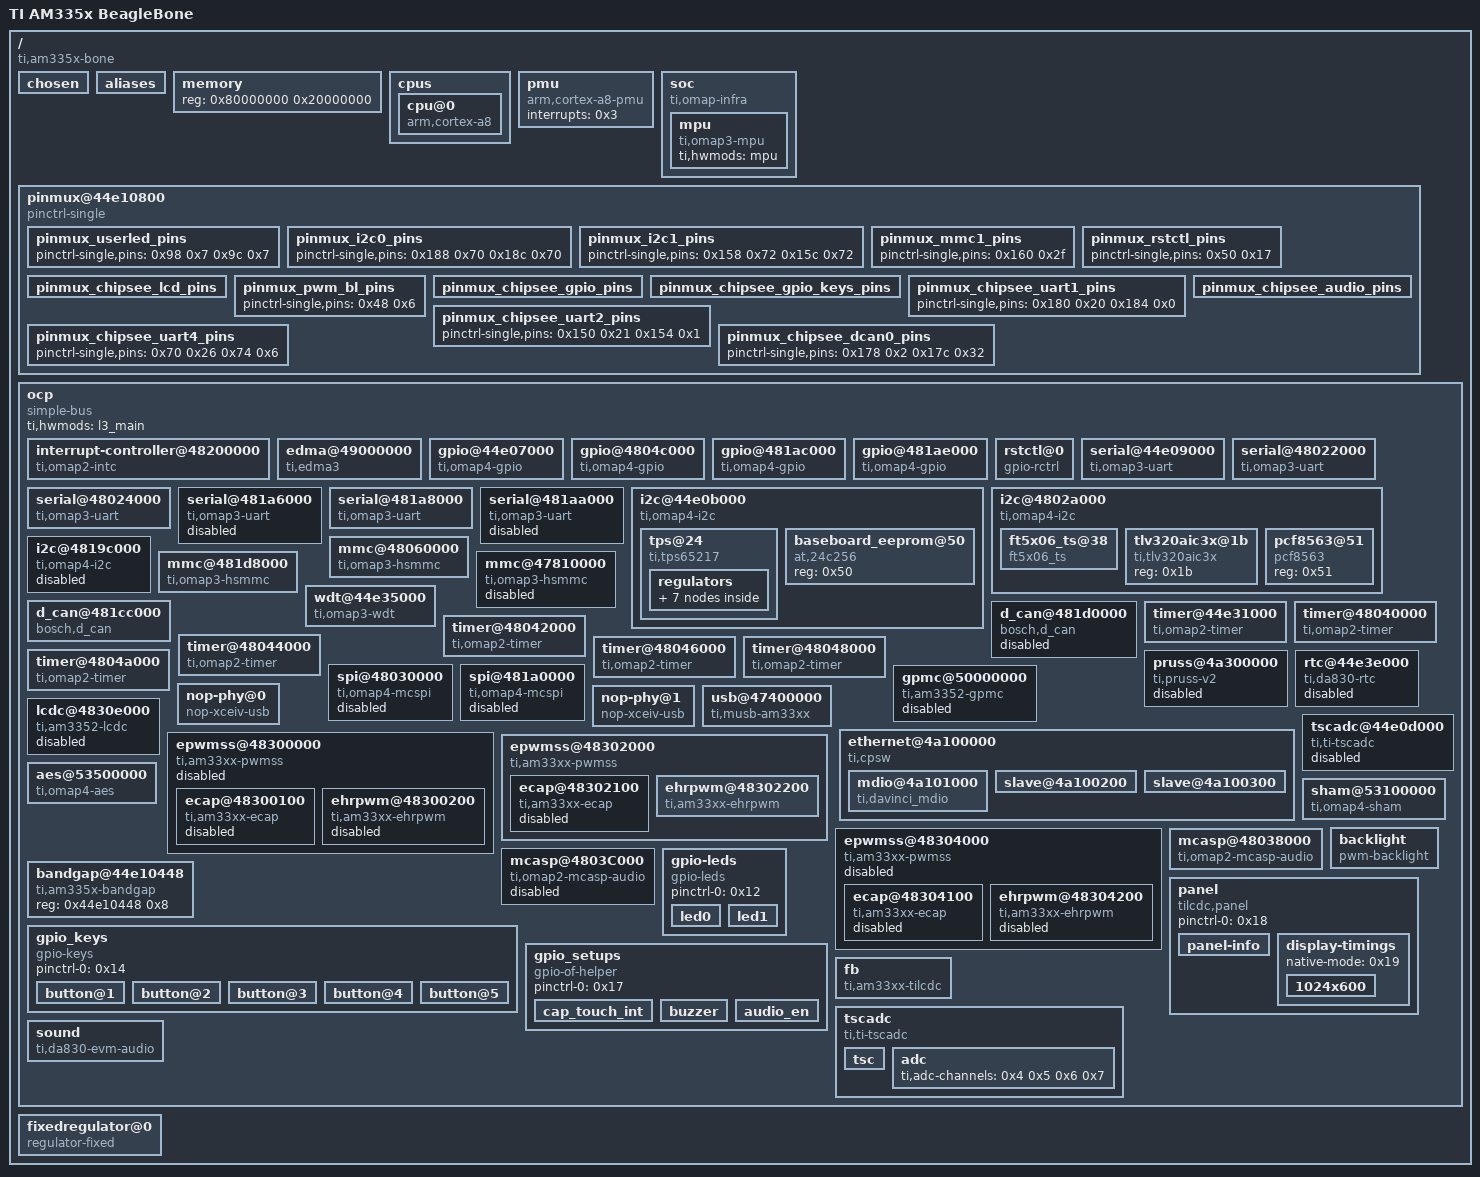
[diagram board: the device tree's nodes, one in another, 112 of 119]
/dts-v1/;

/ {
	#address-cells = <0x1>;
	#size-cells = <0x1>;
	compatible = "ti,am335x-bone", "ti,am33xx";
	interrupt-parent = <0x1>;
	model = "TI AM335x BeagleBone";

	chosen {
	};

	aliases {
		serial0 = "/ocp/serial@44e09000";
		serial1 = "/ocp/serial@48022000";
		serial2 = "/ocp/serial@48024000";
		serial3 = "/ocp/serial@481a6000";
		serial4 = "/ocp/serial@481a8000";
		serial5 = "/ocp/serial@481aa000";
	};

	memory {
		device_type = "memory";
		reg = <0x80000000 0x20000000>;
	};

	cpus {

		cpu@0 {
			compatible = "arm,cortex-a8";
			operating-points = <0xf4240 0x149970 0xc3500 0x13d620 0x927c0 0x10f7c0 0x493e0 0xec928>;
			voltage-tolerance = <0x2>;
			clock-latency = <0x493e0>;
			cpu0-supply = <0x2>;
			linux,phandle = <0x1c>;
			phandle = <0x1c>;
		};
	};

	pmu {
		compatible = "arm,cortex-a8-pmu";
		interrupts = <0x3>;
	};

	soc {
		compatible = "ti,omap-infra";

		mpu {
			compatible = "ti,omap3-mpu";
			ti,hwmods = "mpu";
		};
	};

	pinmux@44e10800 {
		compatible = "pinctrl-single";
		reg = <0x44e10800 0x238>;
		#address-cells = <0x1>;
		#size-cells = <0x0>;
		pinctrl-single,register-width = <0x20>;
		pinctrl-single,function-mask = <0x7f>;
		pinctrl-names = "default";
		linux,phandle = <0x1d>;
		phandle = <0x1d>;

		pinmux_userled_pins {
			pinctrl-single,pins = <0x98 0x7 0x9c 0x7>;
			linux,phandle = <0x12>;
			phandle = <0x12>;
		};

		pinmux_i2c0_pins {
			pinctrl-single,pins = <0x188 0x70 0x18c 0x70>;
			linux,phandle = <0x8>;
			phandle = <0x8>;
		};

		pinmux_i2c1_pins {
			pinctrl-single,pins = <0x158 0x72 0x15c 0x72>;
			linux,phandle = <0x9>;
			phandle = <0x9>;
		};

		pinmux_mmc1_pins {
			pinctrl-single,pins = <0x160 0x2f>;
			linux,phandle = <0xb>;
			phandle = <0xb>;
		};

		pinmux_rstctl_pins {
			pinctrl-single,pins = <0x50 0x17>;
			linux,phandle = <0x3>;
			phandle = <0x3>;
		};

		pinmux_chipsee_lcd_pins {
			pinctrl-single,pins = <0xa0 0x0 0xa4 0x0 0xa8 0x0 0xac 0x0 0xb0 0x0 0xb4 0x0 0xb8 0x0 0xbc 0x0 0xc0 0x0 0xc4 0x0 0xc8 0x0 0xcc 0x0 0xd0 0x0 0xd4 0x0 0xd8 0x0 0xdc 0x0 0x3c 0x11 0x38 0x11 0x34 0x11 0x30 0x11 0x2c 0x11 0x28 0x11 0x24 0x11 0x20 0x11 0xe0 0x0 0xe4 0x0 0xe8 0x0 0xec 0x0>;
			linux,phandle = <0x18>;
			phandle = <0x18>;
		};

		pinmux_pwm_bl_pins {
			pinctrl-single,pins = <0x48 0x6>;
			linux,phandle = <0xf>;
			phandle = <0xf>;
		};

		pinmux_chipsee_gpio_pins {
			pinctrl-single,pins = <0x44 0x27 0x94 0x7 0x90 0x7>;
			linux,phandle = <0x17>;
			phandle = <0x17>;
		};

		pinmux_chipsee_gpio_keys_pins {
			pinctrl-single,pins = <0x164 0x2f 0x78 0x2f 0x40 0x2f 0x4c 0x2f 0x1a4 0x2f>;
			linux,phandle = <0x14>;
			phandle = <0x14>;
		};

		pinmux_chipsee_uart1_pins {
			pinctrl-single,pins = <0x180 0x20 0x184 0x0>;
			linux,phandle = <0x5>;
			phandle = <0x5>;
		};

		pinmux_chipsee_uart2_pins {
			pinctrl-single,pins = <0x150 0x21 0x154 0x1>;
			linux,phandle = <0x6>;
			phandle = <0x6>;
		};

		pinmux_chipsee_uart4_pins {
			pinctrl-single,pins = <0x70 0x26 0x74 0x6>;
			linux,phandle = <0x7>;
			phandle = <0x7>;
		};

		pinmux_chipsee_dcan0_pins {
			pinctrl-single,pins = <0x178 0x2 0x17c 0x32>;
			linux,phandle = <0xd>;
			phandle = <0xd>;
		};

		pinmux_chipsee_audio_pins {
			pinctrl-single,pins = <0x190 0x20 0x194 0x20 0x198 0x20 0x19c 0x22>;
			linux,phandle = <0x10>;
			phandle = <0x10>;
		};
	};
	
	
	
	
	
	
	
	
	
	
	
	
	
	
	
	
	
	
	
	
	ocp {
		compatible = "simple-bus";
		#address-cells = <0x1>;
		#size-cells = <0x1>;
		ranges;
		ti,hwmods = "l3_main";
		linux,phandle = <0x1e>;
		phandle = <0x1e>;

		interrupt-controller@48200000 {
			compatible = "ti,omap2-intc";
			interrupt-controller;
			#interrupt-cells = <0x1>;
			ti,intc-size = <0x80>;
			reg = <0x48200000 0x1000>;
			linux,phandle = <0x1>;
			phandle = <0x1>;
		};

		edma@49000000 {
			compatible = "ti,edma3";
			ti,hwmods = "tpcc", "tptc0", "tptc1", "tptc2";
			reg = <0x49000000 0x10000 0x44e10f90 0x40>;
			interrupt-parent = <0x1>;
			interrupts = <0xc 0xd 0xe>;
			#dma-cells = <0x1>;
			dma-channels = <0x40>;
			ti,edma-regions = <0x4>;
			ti,edma-slots = <0x100>;
			ti,edma-queue-tc-map = <0x0 0x0 0x1 0x1 0x2 0x2>;
			ti,edma-queue-priority-map = <0x0 0x0 0x1 0x1 0x2 0x2>;
			ti,edma-default-queue = <0x1>;
			ti,edma-xbar-event-map = <0x20 0xc 0x1e 0x14>;
			linux,phandle = <0xa>;
			phandle = <0xa>;
		};

		gpio@44e07000 {
			compatible = "ti,omap4-gpio";
			ti,hwmods = "gpio1";
			gpio-controller;
			#gpio-cells = <0x2>;
			interrupt-controller;
			#interrupt-cells = <0x1>;
			reg = <0x44e07000 0x1000>;
			interrupts = <0x60>;
			linux,phandle = <0x15>;
			phandle = <0x15>;
		};

		gpio@4804c000 {
			compatible = "ti,omap4-gpio";
			ti,hwmods = "gpio2";
			gpio-controller;
			#gpio-cells = <0x2>;
			interrupt-controller;
			#interrupt-cells = <0x1>;
			reg = <0x4804c000 0x1000>;
			interrupts = <0x62>;
			linux,phandle = <0x4>;
			phandle = <0x4>;
		};

		gpio@481ac000 {
			compatible = "ti,omap4-gpio";
			ti,hwmods = "gpio3";
			gpio-controller;
			#gpio-cells = <0x2>;
			interrupt-controller;
			#interrupt-cells = <0x1>;
			reg = <0x481ac000 0x1000>;
			interrupts = <0x20>;
			linux,phandle = <0x13>;
			phandle = <0x13>;
		};

		gpio@481ae000 {
			compatible = "ti,omap4-gpio";
			ti,hwmods = "gpio4";
			gpio-controller;
			#gpio-cells = <0x2>;
			interrupt-controller;
			#interrupt-cells = <0x1>;
			reg = <0x481ae000 0x1000>;
			interrupts = <0x3e>;
			linux,phandle = <0x16>;
			phandle = <0x16>;
		};

		rstctl@0 {
			status = "okay";
			compatible = "gpio-rctrl";
			pinctrl-names = "default";
			pinctrl-0 = <0x3>;
			#reset-cells = <0x2>;
			gpios = <0x4 0x14 0x0>;
			gpio-names = "eMMC_RSTn";
			linux,phandle = <0x1f>;
			phandle = <0x1f>;
		};

		serial@44e09000 {
			compatible = "ti,omap3-uart";
			ti,hwmods = "uart1";
			clock-frequency = <0x2dc6c00>;
			reg = <0x44e09000 0x2000>;
			interrupts = <0x48>;
			status = "okay";
			linux,phandle = <0x20>;
			phandle = <0x20>;
		};

		serial@48022000 {
			compatible = "ti,omap3-uart";
			ti,hwmods = "uart2";
			clock-frequency = <0x2dc6c00>;
			reg = <0x48022000 0x2000>;
			interrupts = <0x49>;
			status = "okay";
			pinctrl-names = "default";
			pinctrl-0 = <0x5>;
			linux,phandle = <0x21>;
			phandle = <0x21>;
		};

		serial@48024000 {
			compatible = "ti,omap3-uart";
			ti,hwmods = "uart3";
			clock-frequency = <0x2dc6c00>;
			reg = <0x48024000 0x2000>;
			interrupts = <0x4a>;
			status = "okay";
			pinctrl-names = "default";
			pinctrl-0 = <0x6>;
			linux,phandle = <0x22>;
			phandle = <0x22>;
		};

		serial@481a6000 {
			compatible = "ti,omap3-uart";
			ti,hwmods = "uart4";
			clock-frequency = <0x2dc6c00>;
			reg = <0x481a6000 0x2000>;
			interrupts = <0x2c>;
			status = "disabled";
			linux,phandle = <0x23>;
			phandle = <0x23>;
		};

		serial@481a8000 {
			compatible = "ti,omap3-uart";
			ti,hwmods = "uart5";
			clock-frequency = <0x2dc6c00>;
			reg = <0x481a8000 0x2000>;
			interrupts = <0x2d>;
			status = "okay";
			pinctrl-names = "default";
			pinctrl-0 = <0x7>;
			linux,phandle = <0x24>;
			phandle = <0x24>;
		};

		serial@481aa000 {
			compatible = "ti,omap3-uart";
			ti,hwmods = "uart6";
			clock-frequency = <0x2dc6c00>;
			reg = <0x481aa000 0x2000>;
			interrupts = <0x2e>;
			status = "disabled";
			linux,phandle = <0x25>;
			phandle = <0x25>;
		};

		i2c@44e0b000 {
			compatible = "ti,omap4-i2c";
			#address-cells = <0x1>;
			#size-cells = <0x0>;
			ti,hwmods = "i2c1";
			reg = <0x44e0b000 0x1000>;
			interrupts = <0x46>;
			status = "okay";
			clock-frequency = <0x61a80>;
			pinctrl-names = "default";
			pinctrl-0 = <0x8>;
			linux,phandle = <0x26>;
			phandle = <0x26>;

			tps@24 {
				reg = <0x24>;
				compatible = "ti,tps65217";
				ti,pmic-shutdown-controller;
				interrupt-parent = <0x1>;
				interrupts = <0x7>;
				linux,phandle = <0x27>;
				phandle = <0x27>;

				regulators {
					#address-cells = <0x1>;
					#size-cells = <0x0>;

					regulator@0 {
						reg = <0x0>;
						regulator-compatible = "dcdc1";
						regulator-always-on;
						linux,phandle = <0x28>;
						phandle = <0x28>;
					};

					regulator@1 {
						reg = <0x1>;
						regulator-compatible = "dcdc2";
						regulator-name = "vdd_mpu";
						regulator-min-microvolt = <0xe1d48>;
						regulator-max-microvolt = <0x1437c8>;
						regulator-boot-on;
						regulator-always-on;
						linux,phandle = <0x2>;
						phandle = <0x2>;
					};

					regulator@2 {
						reg = <0x2>;
						regulator-compatible = "dcdc3";
						regulator-name = "vdd_core";
						regulator-min-microvolt = <0xe1d48>;
						regulator-max-microvolt = <0x118c30>;
						regulator-boot-on;
						regulator-always-on;
						linux,phandle = <0x29>;
						phandle = <0x29>;
					};

					regulator@3 {
						reg = <0x3>;
						regulator-compatible = "ldo1";
						regulator-always-on;
						linux,phandle = <0x2a>;
						phandle = <0x2a>;
					};

					regulator@4 {
						reg = <0x4>;
						regulator-compatible = "ldo2";
						regulator-always-on;
						linux,phandle = <0x2b>;
						phandle = <0x2b>;
					};

					regulator@5 {
						reg = <0x5>;
						regulator-compatible = "ldo3";
						regulator-min-microvolt = <0x1b7740>;
						regulator-max-microvolt = <0x1b7740>;
						regulator-always-on;
						linux,phandle = <0x2c>;
						phandle = <0x2c>;
					};

					regulator@6 {
						reg = <0x6>;
						regulator-compatible = "ldo4";
						regulator-always-on;
						linux,phandle = <0x2d>;
						phandle = <0x2d>;
					};
				};
			};

			baseboard_eeprom@50 {
				compatible = "at,24c256";
				reg = <0x50>;
				linux,phandle = <0x2e>;
				phandle = <0x2e>;
			};
		};

		i2c@4802a000 {
			compatible = "ti,omap4-i2c";
			#address-cells = <0x1>;
			#size-cells = <0x0>;
			ti,hwmods = "i2c2";
			reg = <0x4802a000 0x1000>;
			interrupts = <0x47>;
			status = "okay";
			clock-frequency = <0x61a80>;
			pinctrl-names = "default";
			pinctrl-0 = <0x9>;
			linux,phandle = <0x2f>;
			phandle = <0x2f>;

			ft5x06_ts@38 {
				compatible = "ft5x06_ts";
				reg = <0x38>;
				interrupt-parent = <0x4>;
				interrupts = <0x11>;
				linux,phandle = <0x30>;
				phandle = <0x30>;
			};

			tlv320aic3x@1b {
				compatible = "ti,tlv320aic3x";
				reg = <0x1b>;
				status = "okay";
				linux,phandle = <0x1a>;
				phandle = <0x1a>;
			};

			pcf8563@51 {
				compatible = "pcf8563";
				reg = <0x51>;
				status = "okay";
				linux,phandle = <0x31>;
				phandle = <0x31>;
			};
		};

		i2c@4819c000 {
			compatible = "ti,omap4-i2c";
			#address-cells = <0x1>;
			#size-cells = <0x0>;
			ti,hwmods = "i2c3";
			reg = <0x4819c000 0x1000>;
			interrupts = <0x1e>;
			status = "disabled";
			linux,phandle = <0x32>;
			phandle = <0x32>;
		};

		mmc@48060000 {
			compatible = "ti,omap3-hsmmc";
			ti,hwmods = "mmc1";
			ti,dual-volt;
			ti,needs-special-reset;
			ti,needs-special-hs-handling;
			dmas = <0xa 0x18 0xa 0x19>;
			dma-names = "tx", "rx";
			status = "okay";
			pinctrl-names = "default";
			pinctrl-0 = <0xb>;
			bus-width = <0x8>;
			non-removable;
			ti,vcc-aux-disable-is-sleep;
			linux,phandle = <0x33>;
			phandle = <0x33>;
		};

		mmc@481d8000 {
			compatible = "ti,omap3-hsmmc";
			ti,hwmods = "mmc2";
			ti,needs-special-reset;
			ti,needs-special-hs-handling;
			dmas = <0xa 0x2 0xa 0x3>;
			dma-names = "tx", "rx";
			status = "okay";
			vmmc-supply = <0xc>;
			pinctrl-names = "default";
			pinctrl-0 = <0xdeadbeef>;
			bus-width = <0x8>;
			non-removable;
			ti,vcc-aux-disable-is-sleep;
			linux,phandle = <0x34>;
			phandle = <0x34>;
		};

		mmc@47810000 {
			compatible = "ti,omap3-hsmmc";
			ti,hwmods = "mmc3";
			ti,needs-special-reset;
			ti,needs-special-hs-handling;
			status = "disabled";
			linux,phandle = <0x35>;
			phandle = <0x35>;
		};

		wdt@44e35000 {
			compatible = "ti,omap3-wdt";
			ti,hwmods = "wd_timer2";
			reg = <0x44e35000 0x1000>;
			interrupts = <0x5b>;
			linux,phandle = <0x36>;
			phandle = <0x36>;
		};

		d_can@481cc000 {
			compatible = "bosch,d_can";
			ti,hwmods = "d_can0";
			reg = <0x481cc000 0x2000>;
			interrupts = <0x34>;
			status = "okay";
			pinctrl-names = "default";
			pinctrl-0 = <0xd>;
			linux,phandle = <0x37>;
			phandle = <0x37>;
		};

		d_can@481d0000 {
			compatible = "bosch,d_can";
			ti,hwmods = "d_can1";
			reg = <0x481d0000 0x2000>;
			interrupts = <0x37>;
			status = "disabled";
			linux,phandle = <0x38>;
			phandle = <0x38>;
		};

		timer@44e31000 {
			compatible = "ti,omap2-timer";
			reg = <0x44e31000 0x400>;
			interrupts = <0x43>;
			ti,hwmods = "timer1";
			ti,timer-alwon;
			linux,phandle = <0x39>;
			phandle = <0x39>;
		};

		timer@48040000 {
			compatible = "ti,omap2-timer";
			reg = <0x48040000 0x400>;
			interrupts = <0x44>;
			ti,hwmods = "timer2";
			linux,phandle = <0x3a>;
			phandle = <0x3a>;
		};

		timer@48042000 {
			compatible = "ti,omap2-timer";
			reg = <0x48042000 0x400>;
			interrupts = <0x45>;
			ti,hwmods = "timer3";
			linux,phandle = <0x3b>;
			phandle = <0x3b>;
		};

		timer@48044000 {
			compatible = "ti,omap2-timer";
			reg = <0x48044000 0x400>;
			interrupts = <0x5c>;
			ti,hwmods = "timer4";
			ti,timer-pwm;
			linux,phandle = <0x3c>;
			phandle = <0x3c>;
		};

		timer@48046000 {
			compatible = "ti,omap2-timer";
			reg = <0x48046000 0x400>;
			interrupts = <0x5d>;
			ti,hwmods = "timer5";
			ti,timer-pwm;
			linux,phandle = <0x3d>;
			phandle = <0x3d>;
		};

		timer@48048000 {
			compatible = "ti,omap2-timer";
			reg = <0x48048000 0x400>;
			interrupts = <0x5e>;
			ti,hwmods = "timer6";
			ti,timer-pwm;
			linux,phandle = <0x3e>;
			phandle = <0x3e>;
		};

		timer@4804a000 {
			compatible = "ti,omap2-timer";
			reg = <0x4804a000 0x400>;
			interrupts = <0x5f>;
			ti,hwmods = "timer7";
			ti,timer-pwm;
			linux,phandle = <0x3f>;
			phandle = <0x3f>;
		};

		pruss@4a300000 {
			compatible = "ti,pruss-v2";
			ti,hwmods = "pruss";
			ti,deassert-hard-reset = "pruss", "pruss";
			reg = <0x4a300000 0x80000>;
			ti,pintc-offset = <0x20000>;
			interrupt-parent = <0x1>;
			status = "disabled";
			interrupts = <0x14 0x15 0x16 0x17 0x18 0x19 0x1a 0x1b>;
			linux,phandle = <0x40>;
			phandle = <0x40>;
		};

		rtc@44e3e000 {
			compatible = "ti,da830-rtc";
			reg = <0x44e3e000 0x1000>;
			interrupts = <0x4b 0x4c>;
			ti,hwmods = "rtc";
			status = "disabled";
		};

		spi@48030000 {
			compatible = "ti,omap4-mcspi";
			#address-cells = <0x1>;
			#size-cells = <0x0>;
			reg = <0x48030000 0x400>;
			interrupt = <0x41>;
			ti,spi-num-cs = <0x2>;
			ti,hwmods = "spi0";
			dmas = <0xa 0x10 0xa 0x11 0xa 0x12 0xa 0x13>;
			dma-names = "tx0", "rx0", "tx1", "rx1";
			status = "disabled";
			linux,phandle = <0x41>;
			phandle = <0x41>;
		};

		spi@481a0000 {
			compatible = "ti,omap4-mcspi";
			#address-cells = <0x1>;
			#size-cells = <0x0>;
			reg = <0x481a0000 0x400>;
			interrupt = <0x7d>;
			ti,spi-num-cs = <0x2>;
			ti,hwmods = "spi1";
			dmas = <0xa 0x2a 0xa 0x2b 0xa 0x2c 0xa 0x2d>;
			dma-names = "tx0", "rx0", "tx1", "rx1";
			status = "disabled";
			linux,phandle = <0x42>;
			phandle = <0x42>;
		};

		gpmc@50000000 {
			compatible = "ti,am3352-gpmc";
			ti,hwmods = "gpmc";
			reg = <0x50000000 0x1000000>;
			interrupts = <0x64>;
			gpmc,num-cs = <0x7>;
			gpmc,num-waitpins = <0x2>;
			#address-cells = <0x2>;
			#size-cells = <0x1>;
			status = "disabled";
			linux,phandle = <0x43>;
			phandle = <0x43>;
		};

		nop-phy@0 {
			compatible = "nop-xceiv-usb";
		};

		nop-phy@1 {
			compatible = "nop-xceiv-usb";
		};

		usb@47400000 {
			compatible = "ti,musb-am33xx";
			reg = <0x47400000 0x1000 0x47401000 0x800 0x47401800 0x800>;
			interrupts = <0x11 0x12 0x13>;
			multipoint = <0x1>;
			num-eps = <0x10>;
			ram-bits = <0xc>;
			port0-mode = <0x1>;
			port1-mode = <0x1>;
			power = <0xfa>;
			ti,hwmods = "usb_otg_hs";
			status = "okay";
			interface_type = <0x1>;
			linux,phandle = <0x44>;
			phandle = <0x44>;
		};

		ethernet@4a100000 {
			compatible = "ti,cpsw";
			ti,hwmods = "cpgmac0";
			cpdma_channels = <0x8>;
			ale_entries = <0x400>;
			bd_ram_size = <0x2000>;
			no_bd_ram = <0x0>;
			rx_descs = <0x40>;
			mac_control = <0x20>;
			slaves = <0x2>;
			cpts_active_slave = <0x0>;
			cpts_clock_mult = <0x80000000>;
			cpts_clock_shift = <0x1d>;
			reg = <0x4a100000 0x800 0x4a101200 0x100>;
			#address-cells = <0x1>;
			#size-cells = <0x1>;
			interrupt-parent = <0x1>;
			interrupts = <0x28 0x29 0x2a 0x2b>;
			ranges;
			disable-napi;
			linux,phandle = <0x45>;
			phandle = <0x45>;

			mdio@4a101000 {
				compatible = "ti,davinci_mdio";
				#address-cells = <0x1>;
				#size-cells = <0x0>;
				ti,hwmods = "davinci_mdio";
				bus_freq = <0xf4240>;
				reg = <0x4a101000 0x100>;
				linux,phandle = <0xe>;
				phandle = <0xe>;
			};

			slave@4a100200 {
				mac-address = [00 00 00 00 00 00];
				phy_id = <0xe 0x0>;
				linux,phandle = <0x46>;
				phandle = <0x46>;
			};

			slave@4a100300 {
				mac-address = [00 00 00 00 00 00];
				phy_id = <0xe 0x1>;
				linux,phandle = <0x47>;
				phandle = <0x47>;
			};
		};

		tscadc@44e0d000 {
			compatible = "ti,ti-tscadc";
			reg = <0x44e0d000 0x1000>;
			interrupt-parent = <0x1>;
			interrupts = <0x10>;
			ti,hwmods = "adc_tsc";
			status = "disabled";
			linux,phandle = <0x48>;
			phandle = <0x48>;
		};

		lcdc@4830e000 {
			compatible = "ti,am3352-lcdc", "ti,da830-lcdc";
			reg = <0x4830e000 0x1000>;
			interrupts = <0x24>;
			status = "disabled";
			ti,hwmods = "lcdc";
			linux,phandle = <0x49>;
			phandle = <0x49>;
		};

		epwmss@48300000 {
			compatible = "ti,am33xx-pwmss";
			reg = <0x48300000 0x10>;
			ti,hwmods = "epwmss0";
			#address-cells = <0x1>;
			#size-cells = <0x1>;
			status = "disabled";
			ranges = <0x48300100 0x48300100 0x80 0x48300180 0x48300180 0x80 0x48300200 0x48300200 0x80>;
			linux,phandle = <0x4a>;
			phandle = <0x4a>;

			ecap@48300100 {
				compatible = "ti,am33xx-ecap";
				#pwm-cells = <0x3>;
				reg = <0x48300100 0x80>;
				ti,hwmods = "ecap0";
				status = "disabled";
				linux,phandle = <0x4b>;
				phandle = <0x4b>;
			};

			ehrpwm@48300200 {
				compatible = "ti,am33xx-ehrpwm";
				#pwm-cells = <0x3>;
				reg = <0x48300200 0x80>;
				ti,hwmods = "ehrpwm0";
				status = "disabled";
				linux,phandle = <0x4c>;
				phandle = <0x4c>;
			};
		};

		epwmss@48302000 {
			compatible = "ti,am33xx-pwmss";
			reg = <0x48302000 0x10>;
			ti,hwmods = "epwmss1";
			#address-cells = <0x1>;
			#size-cells = <0x1>;
			status = "okay";
			ranges = <0x48302100 0x48302100 0x80 0x48302180 0x48302180 0x80 0x48302200 0x48302200 0x80>;
			linux,phandle = <0x4d>;
			phandle = <0x4d>;

			ecap@48302100 {
				compatible = "ti,am33xx-ecap";
				#pwm-cells = <0x3>;
				reg = <0x48302100 0x80>;
				ti,hwmods = "ecap1";
				status = "disabled";
				linux,phandle = <0x4e>;
				phandle = <0x4e>;
			};

			ehrpwm@48302200 {
				compatible = "ti,am33xx-ehrpwm";
				#pwm-cells = <0x3>;
				reg = <0x48302200 0x80>;
				ti,hwmods = "ehrpwm1";
				status = "okay";
				pinctrl-names = "default";
				pinctrl-0 = <0xf>;
				linux,phandle = <0x11>;
				phandle = <0x11>;
			};
		};

		epwmss@48304000 {
			compatible = "ti,am33xx-pwmss";
			reg = <0x48304000 0x10>;
			ti,hwmods = "epwmss2";
			#address-cells = <0x1>;
			#size-cells = <0x1>;
			status = "disabled";
			ranges = <0x48304100 0x48304100 0x80 0x48304180 0x48304180 0x80 0x48304200 0x48304200 0x80>;
			linux,phandle = <0x4f>;
			phandle = <0x4f>;

			ecap@48304100 {
				compatible = "ti,am33xx-ecap";
				#pwm-cells = <0x3>;
				reg = <0x48304100 0x80>;
				ti,hwmods = "ecap2";
				status = "disabled";
				linux,phandle = <0x50>;
				phandle = <0x50>;
			};

			ehrpwm@48304200 {
				compatible = "ti,am33xx-ehrpwm";
				#pwm-cells = <0x3>;
				reg = <0x48304200 0x80>;
				ti,hwmods = "ehrpwm2";
				status = "disabled";
				linux,phandle = <0x51>;
				phandle = <0x51>;
			};
		};

		sham@53100000 {
			compatible = "ti,omap4-sham";
			ti,hwmods = "sham";
			#address-cells = <0x1>;
			#size-cells = <0x0>;
			reg = <0x53100000 0x200>;
			interrupt-parent = <0x1>;
			interrupts = <0x6d>;
			dmas = <0xa 0x24>;
			dma-names = "rx";
			status = "okay";
			linux,phandle = <0x52>;
			phandle = <0x52>;
		};

		aes@53500000 {
			compatible = "ti,omap4-aes";
			ti,hwmods = "aes";
			#address-cells = <0x1>;
			#size-cells = <0x0>;
			reg = <0x53500000 0xa0>;
			interrupt-parent = <0x1>;
			interrupts = <0x66>;
			dmas = <0xa 0x6 0xa 0x5>;
			dma-names = "tx", "rx";
			status = "okay";
			linux,phandle = <0x53>;
			phandle = <0x53>;
		};

		mcasp@48038000 {
			compatible = "ti,omap2-mcasp-audio";
			#address-cells = <0x1>;
			#size-cells = <0x0>;
			ti,hwmods = "mcasp0";
			reg = <0x48038000 0x2000>;
			interrupts = <0x50 0x51>;
			status = "okay";
			asp-chan-q = <0x2>;
			tx-dma-offset = <0x46000000>;
			rx-dma-offset = <0x46000000>;
			dmas = <0xa 0x8 0xa 0x9>;
			dma-names = "tx", "rx";
			pinctrl-names = "default";
			pinctrl-0 = <0x10>;
			op-mode = <0x0>;
			tdm-slots = <0x2>;
			num-serializer = <0x10>;
			serial-dir = <0x1 0x0 0x2 0x0 0x0 0x0 0x0 0x0 0x0 0x0 0x0 0x0 0x0 0x0 0x0 0x0>;
			tx-num-evt = <0x1>;
			rx-num-evt = <0x1>;
			linux,phandle = <0x1b>;
			phandle = <0x1b>;
		};

		mcasp@4803C000 {
			compatible = "ti,omap2-mcasp-audio";
			#address-cells = <0x1>;
			#size-cells = <0x0>;
			ti,hwmods = "mcasp1";
			reg = <0x4803c000 0x2000>;
			interrupts = <0x52 0x53>;
			status = "disabled";
			asp-chan-q = <0x2>;
			tx-dma-offset = <0x46400000>;
			rx-dma-offset = <0x46400000>;
			dmas = <0xa 0xa 0xa 0xb>;
			dma-names = "tx", "rx";
			linux,phandle = <0x54>;
			phandle = <0x54>;
		};

		bandgap@44e10448 {
			compatible = "ti,am335x-bandgap";
			reg = <0x44e10448 0x8>;
		};

		backlight {
			compatible = "pwm-backlight";
			pwms = <0x11 0x0 0x7a120 0x0>;
			brightness-levels = <0x0 0x1 0x2 0x3 0x4 0x5 0x6 0x7 0x8 0x9 0xa 0xb 0xc 0xd 0xe 0xf 0x10 0x11 0x12 0x13 0x14 0x15 0x16 0x17 0x18 0x19 0x1a 0x1b 0x1c 0x1d 0x1e 0x1f 0x20 0x21 0x22 0x23 0x24 0x25 0x26 0x27 0x28 0x29 0x2a 0x2b 0x2c 0x2d 0x2e 0x2f 0x30 0x31 0x32 0x33 0x34 0x35 0x36 0x37 0x38 0x39 0x3a 0x3b 0x3c 0x3d 0x3e 0x3f 0x40 0x41 0x42 0x43 0x44 0x45 0x46 0x47 0x48 0x49 0x4a 0x4b 0x4c 0x4d 0x4e 0x4f 0x50 0x51 0x52 0x53 0x54 0x55 0x56 0x57 0x58 0x59 0x5a 0x5b 0x5c 0x5d 0x5e 0x5f 0x60 0x61 0x62 0x63 0x64>;
			default-brightness-level = <0x65>;
		};

		gpio-leds {
			compatible = "gpio-leds";
			pinctrl-names = "default";
			pinctrl-0 = <0x12>;

			led0 {
				label = "beaglebone:green:usr0";
				gpios = <0x13 0x4 0x0>;
				linux,default-trigger = "heartbeat";
				default-state = "off";
			};

			led1 {
				label = "beaglebone:green:usr1";
				gpios = <0x13 0x5 0x0>;
				linux,default-trigger = "mmc0";
				default-state = "off";
			};
		};

		gpio_keys {
			compatible = "gpio-keys";
			pinctrl-names = "default";
			pinctrl-0 = <0x14>;
			#address-cells = <0x1>;
			#size-cells = <0x0>;

			button@1 {
				debounce_interval = <0x32>;
				linux,code = <0x69>;
				label = "left";
				gpios = <0x15 0x7 0x1>;
				gpio-key,wakeup;
				autorepeat;
			};

			button@2 {
				debounce_interval = <0x32>;
				linux,code = <0x6a>;
				label = "right";
				gpios = <0x4 0x1c 0x1>;
				gpio-key,wakeup;
				autorepeat;
			};

			button@3 {
				debounce_interval = <0x32>;
				linux,code = <0x67>;
				label = "up";
				gpios = <0x4 0x10 0x1>;
				gpio-key,wakeup;
				autorepeat;
			};

			button@4 {
				debounce_interval = <0x32>;
				linux,code = <0x6c>;
				label = "down";
				gpios = <0x4 0x13 0x1>;
				gpio-key,wakeup;
				autorepeat;
			};

			button@5 {
				debounce_interval = <0x32>;
				linux,code = <0x1c>;
				label = "enter";
				gpios = <0x16 0x13 0x1>;
				gpio-key,wakeup;
			};
		};

		gpio_setups {
			compatible = "gpio-of-helper";
			status = "okay";
			pinctrl-names = "default";
			pinctrl-0 = <0x17>;

			cap_touch_int {
				gpio-name = "cap_touch_int";
				gpio = <0x4 0x11 0x0>;
				input;
			};

			buzzer {
				gpio-name = "buzzer";
				gpio = <0x13 0x3 0x0>;
				output;
				init-low;
			};

			audio_en {
				gpio-name = "audio_enable";
				gpio = <0x13 0x2 0x0>;
				output;
				init-high;
			};
		};

		panel {
			compatible = "tilcdc,panel";
			pinctrl-names = "default";
			pinctrl-0 = <0x18>;

			panel-info {
				ac-bias = <0xff>;
				ac-bias-intrpt = <0x0>;
				dma-burst-sz = <0x10>;
				bpp = <0x20>;
				fdd = <0x80>;
				tft-alt-mode = <0x0>;
				stn-565-mode = <0x0>;
				mono-8bit-mode = <0x0>;
				sync-edge = <0x0>;
				sync-ctrl = <0x0>;
				raster-order = <0x1>;
				fifo-th = <0x0>;
			};

			display-timings {
				native-mode = <0x19>;

				1024x600 {
					hactive = <0x400>;
					vactive = <0x258>;
					hback-porch = <0x2d>;
					hfront-porch = <0x1>;
					hsync-len = <0x1e>;
					vback-porch = <0x16>;
					vfront-porch = <0xc>;
					vsync-len = <0x2>;
					clock-frequency = <0x2255100>;
					hsync-active = <0x1>;
					vsync-active = <0x1>;
					linux,phandle = <0x19>;
					phandle = <0x19>;
				};
			};
		};

		fb {
			compatible = "ti,am33xx-tilcdc";
			reg = <0x4830e000 0x1000>;
			interrupt-parent = <0x1>;
			interrupts = <0x24>;
			ti,hwmods = "lcdc";
			ti,allow-non-reduced-blanking-modes;
		};

		tscadc {
			compatible = "ti,ti-tscadc";
			reg = <0x44e0d000 0x1000>;
			interrupt-parent = <0x1>;
			interrupts = <0x10>;
			ti,hwmods = "adc_tsc";
			status = "okay";

			tsc {
				ti,wires = <0x4>;
				ti,x-plate-resistance = <0xc8>;
				ti,steps-to-config = <0x5>;
				ti,x-min = <0xcb>;
				ti,x-max = <0xfff>;
				ti,x-inverted = <0x0>;
				ti,y-min = <0xc8>;
				ti,y-max = <0xfff>;
				ti,y-inverted = <0x0>;
			};

			adc {
				ti,adc-channels = <0x4 0x5 0x6 0x7>;
			};
		};

		sound {
			compatible = "ti,da830-evm-audio";
			ti,model = "DA830 EVM";
			ti,audio-codec = <0x1a>;
			ti,mcasp-controller = <0x1b>;
			ti,codec-clock-rate = <0xb71b00>;
			ti,audio-routing = "Headphone Jack", "HPLOUT", "Headphone Jack", "HPROUT", "MIC3L", "Mic Bias 2V", "MIC3R", "Mic Bias 2V", "Mic Bias 2V", "Mic Jack";
		};
	};

	fixedregulator@0 {
		compatible = "regulator-fixed";
		regulator-name = "vmmcsd_fixed";
		regulator-min-microvolt = <0x325aa0>;
		regulator-max-microvolt = <0x325aa0>;
		linux,phandle = <0xc>;
		phandle = <0xc>;
	};

	__symbols__ {
		cpu = "/cpus/cpu@0";
		am33xx_pinmux = "/pinmux@44e10800";
		userled_pins = "/pinmux@44e10800/pinmux_userled_pins";
		i2c0_pins = "/pinmux@44e10800/pinmux_i2c0_pins";
		i2c1_pins = "/pinmux@44e10800/pinmux_i2c1_pins";
		mmc1_pins = "/pinmux@44e10800/pinmux_mmc1_pins";
		rstctl_pins = "/pinmux@44e10800/pinmux_rstctl_pins";
		chipsee_lcd_pins = "/pinmux@44e10800/pinmux_chipsee_lcd_pins";
		pwm_bl_pins = "/pinmux@44e10800/pinmux_pwm_bl_pins";
		chipsee_gpio_pins = "/pinmux@44e10800/pinmux_chipsee_gpio_pins";
		chipsee_gpio_keys_pins = "/pinmux@44e10800/pinmux_chipsee_gpio_keys_pins";
		chipsee_uart1_pins = "/pinmux@44e10800/pinmux_chipsee_uart1_pins";
		chipsee_uart2_pins = "/pinmux@44e10800/pinmux_chipsee_uart2_pins";
		chipsee_uart4_pins = "/pinmux@44e10800/pinmux_chipsee_uart4_pins";
		chipsee_dcan0_pins = "/pinmux@44e10800/pinmux_chipsee_dcan0_pins";
		chipsee_audio_pins = "/pinmux@44e10800/pinmux_chipsee_audio_pins";
		ocp = "/ocp";
		intc = "/ocp/interrupt-controller@48200000";
		edma = "/ocp/edma@49000000";
		gpio1 = "/ocp/gpio@44e07000";
		gpio2 = "/ocp/gpio@4804c000";
		gpio3 = "/ocp/gpio@481ac000";
		gpio4 = "/ocp/gpio@481ae000";
		rstctl = "/ocp/rstctl@0";
		uart1 = "/ocp/serial@44e09000";
		uart2 = "/ocp/serial@48022000";
		uart3 = "/ocp/serial@48024000";
		uart4 = "/ocp/serial@481a6000";
		uart5 = "/ocp/serial@481a8000";
		uart6 = "/ocp/serial@481aa000";
		i2c0 = "/ocp/i2c@44e0b000";
		tps = "/ocp/i2c@44e0b000/tps@24";
		dcdc1_reg = "/ocp/i2c@44e0b000/tps@24/regulators/regulator@0";
		dcdc2_reg = "/ocp/i2c@44e0b000/tps@24/regulators/regulator@1";
		dcdc3_reg = "/ocp/i2c@44e0b000/tps@24/regulators/regulator@2";
		ldo1_reg = "/ocp/i2c@44e0b000/tps@24/regulators/regulator@3";
		ldo2_reg = "/ocp/i2c@44e0b000/tps@24/regulators/regulator@4";
		ldo3_reg = "/ocp/i2c@44e0b000/tps@24/regulators/regulator@5";
		ldo4_reg = "/ocp/i2c@44e0b000/tps@24/regulators/regulator@6";
		baseboard_eeprom = "/ocp/i2c@44e0b000/baseboard_eeprom@50";
		i2c1 = "/ocp/i2c@4802a000";
		ft5x06_ts = "/ocp/i2c@4802a000/ft5x06_ts@38";
		tlv320aic3x = "/ocp/i2c@4802a000/tlv320aic3x@1b";
		pcf8563 = "/ocp/i2c@4802a000/pcf8563@51";
		i2c2 = "/ocp/i2c@4819c000";
		mmc1 = "/ocp/mmc@48060000";
		mmc2 = "/ocp/mmc@481d8000";
		mmc3 = "/ocp/mmc@47810000";
		wdt2 = "/ocp/wdt@44e35000";
		dcan0 = "/ocp/d_can@481cc000";
		dcan1 = "/ocp/d_can@481d0000";
		timer1 = "/ocp/timer@44e31000";
		timer2 = "/ocp/timer@48040000";
		timer3 = "/ocp/timer@48042000";
		timer4 = "/ocp/timer@48044000";
		timer5 = "/ocp/timer@48046000";
		timer6 = "/ocp/timer@48048000";
		timer7 = "/ocp/timer@4804a000";
		pruss = "/ocp/pruss@4a300000";
		spi0 = "/ocp/spi@48030000";
		spi1 = "/ocp/spi@481a0000";
		gpmc = "/ocp/gpmc@50000000";
		usb_otg_hs = "/ocp/usb@47400000";
		mac = "/ocp/ethernet@4a100000";
		davinci_mdio = "/ocp/ethernet@4a100000/mdio@4a101000";
		cpsw_emac0 = "/ocp/ethernet@4a100000/slave@4a100200";
		cpsw_emac1 = "/ocp/ethernet@4a100000/slave@4a100300";
		tscadc = "/ocp/tscadc@44e0d000";
		lcdc = "/ocp/lcdc@4830e000";
		epwmss0 = "/ocp/epwmss@48300000";
		ecap0 = "/ocp/epwmss@48300000/ecap@48300100";
		ehrpwm0 = "/ocp/epwmss@48300000/ehrpwm@48300200";
		epwmss1 = "/ocp/epwmss@48302000";
		ecap1 = "/ocp/epwmss@48302000/ecap@48302100";
		ehrpwm1 = "/ocp/epwmss@48302000/ehrpwm@48302200";
		epwmss2 = "/ocp/epwmss@48304000";
		ecap2 = "/ocp/epwmss@48304000/ecap@48304100";
		ehrpwm2 = "/ocp/epwmss@48304000/ehrpwm@48304200";
		sham = "/ocp/sham@53100000";
		aes = "/ocp/aes@53500000";
		mcasp0 = "/ocp/mcasp@48038000";
		mcasp1 = "/ocp/mcasp@4803C000";
		timing0 = "/ocp/panel/display-timings/1024x600";
		vmmcsd_fixed = "/fixedregulator@0";
	};

	__fixups__ {
		mmc_pins = "/ocp/mmc@481d8000:pinctrl-0:0";
	};
};
